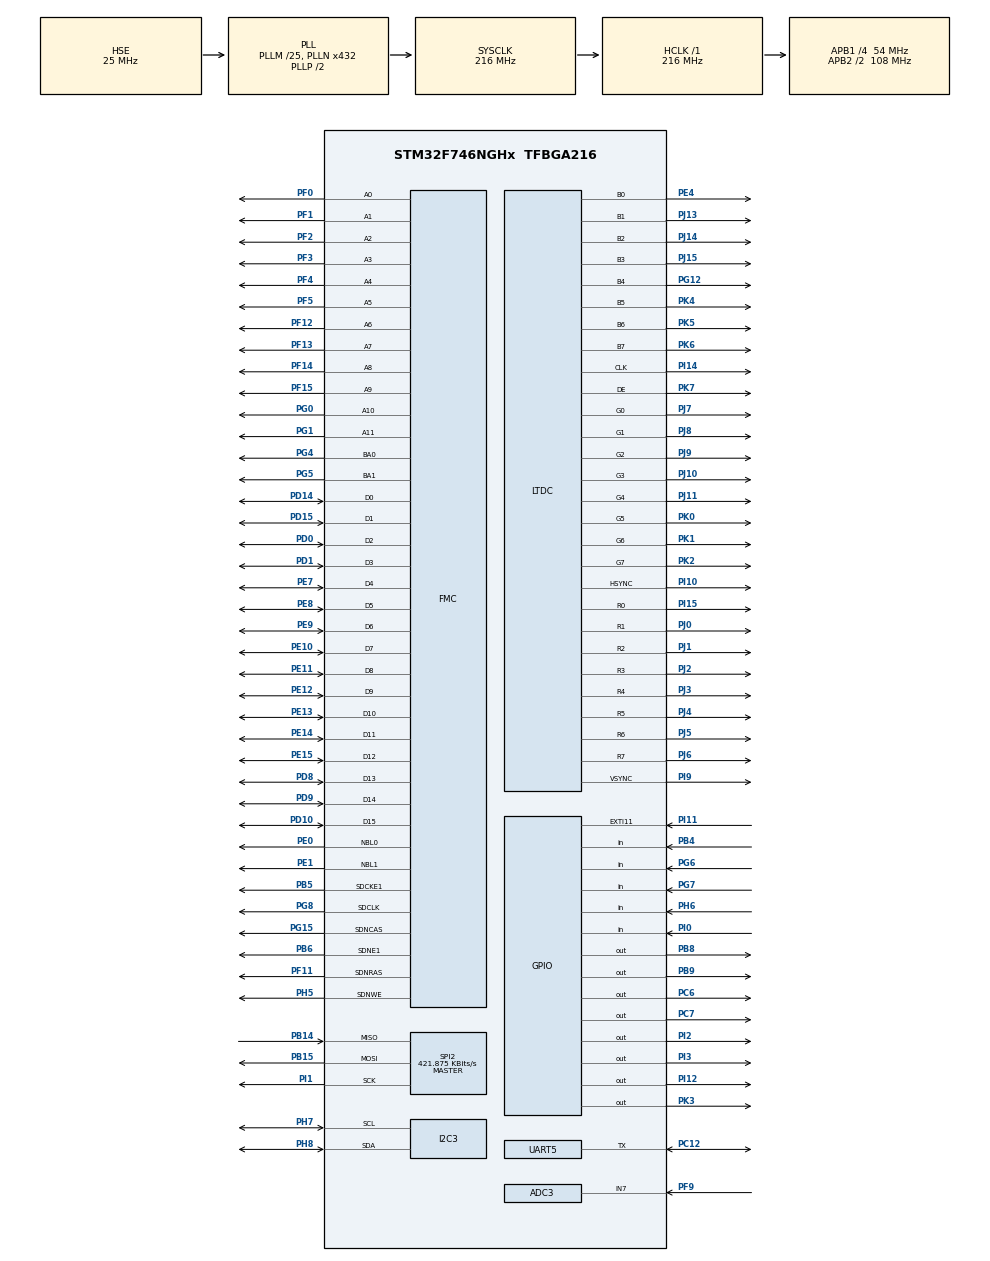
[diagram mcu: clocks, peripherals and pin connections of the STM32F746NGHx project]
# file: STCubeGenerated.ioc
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ADC3.Channel-0\#ChannelRegularConversion=ADC_CHANNEL_7
ADC3.ClockPrescaler=ADC_CLOCK_SYNC_PCLK_DIV4
ADC3.ContinuousConvMode=ENABLE
ADC3.DMAContinuousRequests=ENABLE
ADC3.DataAlign=ADC_DATAALIGN_RIGHT
ADC3.DiscontinuousConvMode=DISABLE
ADC3.EOCSelection=ADC_EOC_SINGLE_CONV
ADC3.EnableAnalogWatchDog=false
ADC3.ExternalTrigConv=ADC_SOFTWARE_START
ADC3.ExternalTrigConvEdge=ADC_EXTERNALTRIGCONVEDGE_NONE
ADC3.InjNumberOfConversion=0
ADC3.NbrOfConversion=1
ADC3.NbrOfConversionFlag=1
ADC3.Rank-0\#ChannelRegularConversion=1
ADC3.Resolution=ADC_RESOLUTION_8B
ADC3.SamplingTime-0\#ChannelRegularConversion=ADC_SAMPLETIME_3CYCLES
ADC3.ScanConvMode=ENABLE
CORTEX_M7.ART_ACCLERATOR_ENABLE=1
CORTEX_M7.AccessPermission-Cortex_Memory_Protection_Unit_Region0_Settings=MPU_REGION_FULL_ACCESS
CORTEX_M7.BaseAddress-Cortex_Memory_Protection_Unit_Region0_Settings=0x20010000
CORTEX_M7.CPU_DCache=Enabled
CORTEX_M7.CPU_ICache=Enabled
CORTEX_M7.Enable-Cortex_Memory_Protection_Unit_Region0_Settings=MPU_REGION_ENABLE
CORTEX_M7.IsCacheable-Cortex_Memory_Protection_Unit_Region0_Settings=MPU_ACCESS_CACHEABLE
CORTEX_M7.MPU_Control=__NULL
CORTEX_M7.PREFETCH_ENABLE=1
CORTEX_M7.Size-Cortex_Memory_Protection_Unit_Region0_Settings=MPU_REGION_SIZE_256KB
DMA2D.ColorMode=DMA2D_OUTPUT_ARGB8888
Dma.ADC3.0.Direction=DMA_PERIPH_TO_MEMORY
Dma.ADC3.0.FIFOMode=DMA_FIFOMODE_DISABLE
Dma.ADC3.0.Instance=DMA2_Stream1
Dma.ADC3.0.MemDataAlignment=DMA_MDATAALIGN_WORD
Dma.ADC3.0.MemInc=DMA_MINC_ENABLE
Dma.ADC3.0.Mode=DMA_NORMAL
Dma.ADC3.0.PeriphDataAlignment=DMA_PDATAALIGN_WORD
Dma.ADC3.0.PeriphInc=DMA_PINC_DISABLE
Dma.ADC3.0.Priority=DMA_PRIORITY_VERY_HIGH
Dma.Request0=ADC3
I2C3.Timing=0x20404768
LTDC.ActiveH=272
LTDC.ActiveW=480
LTDC.Alpha_L0=255
LTDC.HBP=13
LTDC.HFP=32
LTDC.HSync=41
LTDC.ImageHeight_L0=272
LTDC.ImageWidth_L0=480
LTDC.Layers=0
LTDC.VSync=10
LTDC.WindowX1_L0=480
LTDC.WindowY1_L0=272
Mcu.Family=STM32F7
Mcu.Name=STM32F746NGHx
Mcu.Package=TFBGA216
NVIC.DMA2_Stream1_IRQn=true\:1\:0\:true\:false\:true\:true
NVIC.EXTI15_10_IRQn=true\:0\:0\:false\:false\:true\:true
NVIC.PriorityGroup=NVIC_PRIORITYGROUP_4
PA13.Mode=Trace_Asynchronous_SW
PA13.Signal=SYS_JTMS-SWDIO
PA14.Mode=Trace_Asynchronous_SW
PA14.Signal=SYS_JTCK-SWCLK
PB14.Mode=Full_Duplex_Master
PB14.Signal=SPI2_MISO
PB15.Mode=Full_Duplex_Master
PB15.Signal=SPI2_MOSI
PB3.Mode=Trace_Asynchronous_SW
PB3.Signal=SYS_JTDO-SWO
PB4.Signal=GPIO_Input
PB5.Mode=SdramChipSelect2_1
PB5.Signal=FMC_SDCKE1
PB6.Mode=SdramChipSelect2_1
PB6.Signal=FMC_SDNE1
PB8.Signal=GPIO_Output
PB9.Signal=GPIO_Output
PC12.Mode=Half_duplex(single_wire_mode)
PC12.Signal=UART5_TX
PC14/OSC32_IN.Mode=LSE-External-Oscillator
PC14/OSC32_IN.Signal=RCC_OSC32_IN
PC15/OSC32_OUT.Mode=LSE-External-Oscillator
PC15/OSC32_OUT.Signal=RCC_OSC32_OUT
PC6.Signal=GPIO_Output
PC7.Signal=GPIO_Output
PD0.Signal=FMC_D2_DA2
PD1.Signal=FMC_D3_DA3
PD10.Signal=FMC_D15_DA15
PD14.Signal=FMC_D0_DA0
PD15.Signal=FMC_D1_DA1
PD8.Signal=FMC_D13_DA13
PD9.Signal=FMC_D14_DA14
PE0.Signal=FMC_NBL0
PE1.Signal=FMC_NBL1
PE10.Signal=FMC_D7_DA7
PE11.Signal=FMC_D8_DA8
PE12.Signal=FMC_D9_DA9
PE13.Signal=FMC_D10_DA10
PE14.Signal=FMC_D11_DA11
PE15.Signal=FMC_D12_DA12
PE4.Mode=RGB888
PE4.Signal=LTDC_B0
PE7.Signal=FMC_D4_DA4
PE8.Signal=FMC_D5_DA5
PE9.Signal=FMC_D6_DA6
PF0.Signal=FMC_A0
PF1.Signal=FMC_A1
PF11.Signal=FMC_SDNRAS
PF12.Signal=FMC_A6
PF13.Signal=FMC_A7
PF14.Signal=FMC_A8
PF15.Signal=FMC_A9
PF2.Signal=FMC_A2
PF3.Signal=FMC_A3
PF4.Signal=FMC_A4
PF5.Signal=FMC_A5
PF9.Mode=IN7
PF9.Signal=ADC3_IN7
PG0.Signal=FMC_A10
PG1.Signal=FMC_A11
PG12.Mode=RGB888
PG12.Signal=LTDC_B4
PG15.Signal=FMC_SDNCAS
PG4.Signal=FMC_A14_BA0
PG5.Signal=FMC_A15_BA1
PG6.Signal=GPIO_Input
PG7.Signal=GPIO_Input
PG8.Signal=FMC_SDCLK
PH0/OSC_IN.Mode=HSE-External-Oscillator
PH0/OSC_IN.Signal=RCC_OSC_IN
PH1/OSC_OUT.Mode=HSE-External-Oscillator
PH1/OSC_OUT.Signal=RCC_OSC_OUT
PH5.Signal=FMC_SDNWE
PH6.Signal=GPIO_Input
PH7.Mode=I2C
PH7.Signal=I2C3_SCL
PH8.Mode=I2C
PH8.Signal=I2C3_SDA
PI0.Signal=GPIO_Input
PI1.Mode=Full_Duplex_Master
PI1.Signal=SPI2_SCK
PI10.Mode=RGB888
PI10.Signal=LTDC_HSYNC
PI11.Signal=GPXTI11
PI12.GPIO_Speed=GPIO_SPEED_FREQ_HIGH
PI12.PinState=GPIO_PIN_SET
PI12.Signal=GPIO_Output
PI14.Mode=RGB888
PI14.Signal=LTDC_CLK
PI15.Mode=RGB888
PI15.Signal=LTDC_R0
PI2.Signal=GPIO_Output
PI3.Signal=GPIO_Output
PI9.Mode=RGB888
PI9.Signal=LTDC_VSYNC
PJ0.Mode=RGB888
PJ0.Signal=LTDC_R1
PJ1.Mode=RGB888
PJ1.Signal=LTDC_R2
PJ10.Mode=RGB888
PJ10.Signal=LTDC_G3
PJ11.Mode=RGB888
PJ11.Signal=LTDC_G4
PJ13.Mode=RGB888
PJ13.Signal=LTDC_B1
PJ14.Mode=RGB888
PJ14.Signal=LTDC_B2
PJ15.Mode=RGB888
PJ15.Signal=LTDC_B3
PJ2.Mode=RGB888
PJ2.Signal=LTDC_R3
PJ3.Mode=RGB888
PJ3.Signal=LTDC_R4
PJ4.Mode=RGB888
PJ4.Signal=LTDC_R5
PJ5.Mode=RGB888
PJ5.Signal=LTDC_R6
PJ6.Mode=RGB888
PJ6.Signal=LTDC_R7
PJ7.Mode=RGB888
PJ7.Signal=LTDC_G0
PJ8.Mode=RGB888
PJ8.Signal=LTDC_G1
PJ9.Mode=RGB888
PJ9.Signal=LTDC_G2
PK0.Mode=RGB888
PK0.Signal=LTDC_G5
PK1.Mode=RGB888
PK1.Signal=LTDC_G6
PK2.Mode=RGB888
PK2.Signal=LTDC_G7
PK3.GPIO_Speed=GPIO_SPEED_FREQ_HIGH
PK3.PinState=GPIO_PIN_SET
PK3.Signal=GPIO_Output
PK4.Mode=RGB888
PK4.Signal=LTDC_B5
PK5.Mode=RGB888
PK5.Signal=LTDC_B6
PK6.Mode=RGB888
PK6.Signal=LTDC_B7
PK7.Mode=RGB888
PK7.Signal=LTDC_DE
ProjectManager.HeapSize=0x200
ProjectManager.StackSize=0x400
ProjectManager.TargetToolchain=MDK-ARM V5
RCC.AHBFreq_Value=216000000
RCC.APB1CLKDivider=RCC_HCLK_DIV4
RCC.APB1Freq_Value=54000000
RCC.APB1TimFreq_Value=108000000
RCC.APB2CLKDivider=RCC_HCLK_DIV2
RCC.APB2Freq_Value=108000000
RCC.APB2TimFreq_Value=216000000
RCC.CortexFreq_Value=27000000
RCC.Cortex_Div=SYSTICK_CLKSOURCE_HCLK_DIV8
RCC.HCLKFreq_Value=216000000
RCC.HSE_VALUE=25000000
RCC.HSI_VALUE=16000000
RCC.PLLI2SP=RCC_PLLP_DIV2
RCC.PLLM=25
RCC.PLLN=432
RCC.PLLQ=9
RCC.PLLSAIN=100
RCC.PLLSAIP=RCC_PLLSAIP_DIV2
RCC.PLLSourceVirtual=RCC_PLLSOURCE_HSE
RCC.RCC_MCODiv1=RCC_MCODIV_1
RCC.RCC_MCODiv2=RCC_MCODIV_1
RCC.RCC_RTC_Clock_Source_FROM_HSE=RCC_RTCCLKSOURCE_HSE_DIV2
RCC.SYSCLKFreq_VALUE=216000000
RCC.SYSCLKSource=RCC_SYSCLKSOURCE_PLLCLK
RCC.USBFreq_Value=48000000
RCC.VCOOutputFreq_Value=432000000
SH.FMC_A0.0=FMC_A0,12b-sda1
SH.FMC_A1.0=FMC_A1,12b-sda1
SH.FMC_A10.0=FMC_A10,12b-sda1
SH.FMC_A11.0=FMC_A11,12b-sda1
SH.FMC_A14_BA0.0=FMC_BA0,FourSdramBanks1
SH.FMC_A15_BA1.0=FMC_BA1,FourSdramBanks1
SH.FMC_A2.0=FMC_A2,12b-sda1
SH.FMC_A3.0=FMC_A3,12b-sda1
SH.FMC_A4.0=FMC_A4,12b-sda1
SH.FMC_A5.0=FMC_A5,12b-sda1
SH.FMC_A6.0=FMC_A6,12b-sda1
SH.FMC_A7.0=FMC_A7,12b-sda1
SH.FMC_A8.0=FMC_A8,12b-sda1
SH.FMC_A9.0=FMC_A9,12b-sda1
SH.FMC_D0_DA0.0=FMC_D0,sd-16b-d1
SH.FMC_D10_DA10.0=FMC_D10,sd-16b-d1
SH.FMC_D11_DA11.0=FMC_D11,sd-16b-d1
SH.FMC_D12_DA12.0=FMC_D12,sd-16b-d1
SH.FMC_D13_DA13.0=FMC_D13,sd-16b-d1
SH.FMC_D14_DA14.0=FMC_D14,sd-16b-d1
SH.FMC_D15_DA15.0=FMC_D15,sd-16b-d1
SH.FMC_D1_DA1.0=FMC_D1,sd-16b-d1
SH.FMC_D2_DA2.0=FMC_D2,sd-16b-d1
SH.FMC_D3_DA3.0=FMC_D3,sd-16b-d1
SH.FMC_D4_DA4.0=FMC_D4,sd-16b-d1
SH.FMC_D5_DA5.0=FMC_D5,sd-16b-d1
SH.FMC_D6_DA6.0=FMC_D6,sd-16b-d1
SH.FMC_D7_DA7.0=FMC_D7,sd-16b-d1
SH.FMC_D8_DA8.0=FMC_D8,sd-16b-d1
SH.FMC_D9_DA9.0=FMC_D9,sd-16b-d1
SH.FMC_NBL0.0=FMC_NBL0,Sd2ByteEnable1
SH.FMC_NBL1.0=FMC_NBL1,Sd2ByteEnable1
SH.FMC_SDCLK.0=FMC_SDCLK,12b-sda1
SH.FMC_SDNCAS.0=FMC_SDNCAS,12b-sda1
SH.FMC_SDNRAS.0=FMC_SDNRAS,12b-sda1
SH.FMC_SDNWE.0=FMC_SDNWE,12b-sda1
SPI2.BaudRatePrescaler=SPI_BAUDRATEPRESCALER_128
SPI2.CalculateBaudRate=421.875 KBits/s
SPI2.DataSize=SPI_DATASIZE_16BIT
SPI2.Direction=SPI_DIRECTION_2LINES
SPI2.Mode=SPI_MODE_MASTER
SPI2.VirtualType=VM_MASTER
VP_DMA2D_VS_DMA2D.Mode=DMA2D_Activate
board=STCubeGenerated

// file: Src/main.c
/**
  ******************************************************************************
  * File Name          : main.c
  * Description        : Main program body
  ******************************************************************************
  ** This notice applies to any and all portions of this file
  * that are not between comment pairs USER CODE BEGIN and
  * USER CODE END. Other portions of this file, whether
  * inserted by the user or by software development tools
  * are owned by their respective copyright owners.
  *
  * COPYRIGHT(c) 2018 STMicroelectronics
  *
  * Redistribution and use in source and binary forms, with or without modification,
  * are permitted provided that the following conditions are met:
  *   1. Redistributions of source code must retain the above copyright notice,
  *      this list of conditions and the following disclaimer.
  *   2. Redistributions in binary form must reproduce the above copyright notice,
  *      this list of conditions and the following disclaimer in the documentation
  *      and/or other materials provided with the distribution.
  *   3. Neither the name of STMicroelectronics nor the names of its contributors
  *      may be used to endorse or promote products derived from this software
  *      without specific prior written permission.
  *
  * THIS SOFTWARE IS PROVIDED BY THE COPYRIGHT HOLDERS AND CONTRIBUTORS "AS IS"
  * AND ANY EXPRESS OR IMPLIED WARRANTIES, INCLUDING, BUT NOT LIMITED TO, THE
  * IMPLIED WARRANTIES OF MERCHANTABILITY AND FITNESS FOR A PARTICULAR PURPOSE ARE
  * DISCLAIMED. IN NO EVENT SHALL THE COPYRIGHT HOLDER OR CONTRIBUTORS BE LIABLE
  * FOR ANY DIRECT, INDIRECT, INCIDENTAL, SPECIAL, EXEMPLARY, OR CONSEQUENTIAL
  * DAMAGES (INCLUDING, BUT NOT LIMITED TO, PROCUREMENT OF SUBSTITUTE GOODS OR
  * SERVICES; LOSS OF USE, DATA, OR PROFITS; OR BUSINESS INTERRUPTION) HOWEVER
  * CAUSED AND ON ANY THEORY OF LIABILITY, WHETHER IN CONTRACT, STRICT LIABILITY,
  * OR TORT (INCLUDING NEGLIGENCE OR OTHERWISE) ARISING IN ANY WAY OUT OF THE USE
  * OF THIS SOFTWARE, EVEN IF ADVISED OF THE POSSIBILITY OF SUCH DAMAGE.
  *
  ******************************************************************************
  */

#include "main.h"
#include "stm32f7xx_hal.h"

/* USER CODE BEGIN Includes */
#include "stm32746g_discovery_lcd.h"
#include "stm32746g_discovery_ts.h"
#include "splash.h"
#include "gui.h"
#include "ft5336.h"
#include "RGB565_320x240.h"
#include "spi.h"
#include "stm32f7xx_it.h"
#define ITM_Port8(n) (*((volatile unsigned char *)(0xE0000000+4*n)))
/* USER CODE END Includes */

ADC_HandleTypeDef hadc3;
DMA_HandleTypeDef hdma_adc3;

DMA2D_HandleTypeDef hdma2d;

I2C_HandleTypeDef hi2c3;

LTDC_HandleTypeDef hltdc;

SPI_HandleTypeDef hspi2;

UART_HandleTypeDef huart5;

SDRAM_HandleTypeDef hsdram1;

/* USER CODE BEGIN PV */
/* Private variables ---------------------------------------------------------*/
extern uint32_t DMA_compl;

uint32_t no_sample_points = 32768;

uint32_t ADC3ConvertedValues[80000]; //array to store ADC values from DMA

uint32_t TSConvertedValues[2048]; //array to store TS values from DMA

uint32_t run_state = 0; //variable used to store start/stop state 0=stopped, 1=running

uint32_t pga_gain[6] = {0,1,2,3,4,5}; //Gain=1,2,4,5,8,10,16,32

float time_div[8] = {0.25,0.5,1,2.5,5,10,25,50}; //stores t/div shift

uint32_t time_div_selected = 2; //stores which t/div mode is currently selected

int32_t v_shift = 0; //stores vertical offset, (20+)221 = centre of trace area

int32_t h_shift = 0; //stores horizontal offset

uint16_t x, y; //variables to store x,y co-ordinates when user presses touchscreen

uint32_t i_min = 20; //stores the start point of data to plot

uint32_t i_max = 462; //stores the end point of data to plot

int32_t trig_level = 100; //stores the trigger level

uint32_t trigset=0;	//stores the trigger state, 1=set, 0=not set

uint16_t pga_gain_selected = 0;	//stores the current point in the gain array selected

uint32_t attenuation = 1; //1= 1:1, 10= 1:10

uint32_t coup_mode = 0; //stores current coupling mode, 0 = dc, 1 = ac

/* USER CODE END PV */

void SystemClock_Config(void);
static void MX_GPIO_Init(void);
static void MX_DMA_Init(void);
static void MX_ADC3_Init(void);
static void MX_DMA2D_Init(void);
static void MX_FMC_Init(void);
static void MX_LTDC_Init(void);
static void MX_UART5_Init(void);
static void MX_I2C3_Init(void);
static void MX_SPI2_Init(void);

/* USER CODE BEGIN PFP */
void startadc3 (void);
void stopadc3 (void);
/* Private function prototypes -----------------------------------------------*/

/* USER CODE END PFP */

int main(void)
{

  /* Enable I-Cache-------------------------------------------------------------*/
  SCB_EnableICache();

  /* Enable D-Cache-------------------------------------------------------------*/
  SCB_EnableDCache();

  /* MCU Configuration----------------------------------------------------------*/

  /* Reset of all peripherals, Initializes the Flash interface and the Systick. */
  HAL_Init();

  /* Configure the system clock */
  SystemClock_Config();

  /* Initialize all configured peripherals */
  MX_GPIO_Init();
  MX_DMA_Init();
  MX_ADC3_Init();
  MX_DMA2D_Init();
  MX_FMC_Init();
  MX_LTDC_Init();
  MX_UART5_Init();
  MX_I2C3_Init();
  MX_SPI2_Init();

  /* USER CODE BEGIN 2 */

	/*
	// output to the Debug viewer using the ITM
	ITM_Port8(0) = 'a';
	while (ITM_Port8(0) == 0);
	ITM_Port8(0) = 0x0D;
	while (ITM_Port8(0) == 0);
	ITM_Port8(0) = 0x0A;
	*/
  /* LCD Initialization */
	BSP_LCD_Init();
	BSP_LCD_LayerDefaultInit(0, LCD_FB_START_ADDRESS);

  /* Enable the LCD */
  BSP_LCD_DisplayOn();

 /* Configure Front layer (0) */
  BSP_LCD_SelectLayer(0);
  /* Clear the Background Layer */
  BSP_LCD_Clear(LCD_COLOR_BLACK);
  //BSP_LCD_SetTransparency(1,0xFF);
	BSP_LCD_SetTextColor(LCD_COLOR_WHITE);
	BSP_LCD_SetBackColor(LCD_COLOR_BLACK);

	//Initialise Touch Screen
	BSP_TS_Init(480,272);
	printf("LCD initialisation complete\n");

  printf("Waiting for user to dismiss splash screen\n");
	printf("Ensure that AFE is connected\n");

	//Display splash screen on LCD
	drawsplash();

	/* SPI Peripheral Initialisation */
	/* Set the CS high (disable) for DAC & PGA*/
	HAL_GPIO_WritePin(GPIOI, GPIO_PIN_2, GPIO_PIN_SET);
	HAL_GPIO_WritePin(GPIOI, GPIO_PIN_3, GPIO_PIN_SET);

	//Initialise the DAC and PGA
	dac_set_level(0); //zero offset (Vref = 0 V)
	pga_control(0); //zero gain

	/* Initialise the AFE auto-switching as disabled */
	HAL_GPIO_WritePin(GPIOC, GPIO_PIN_6, GPIO_PIN_SET);
	HAL_GPIO_WritePin(GPIOC, GPIO_PIN_7, GPIO_PIN_SET);

	printf("DAC & PGA initialised\n");

  /* Configure Background Layer (1) */
	/* Comment out the following line to disable the background
	   - reduces programming time during testing */
  BSP_LCD_LayerRgb565Init(1, (uint32_t)&RGB565_320x240);
	BSP_LCD_SetTransparency(1, 80);

	//Initialise touch screen in interrupt mode
	BSP_TS_ITConfig();

	cleartrace(); //clear the trace area
	run_state = 1; //Initially start the DSO with trace running
	startadc3(); //start ADC3
	printf("Init completed; DSO started\n");

  /* USER CODE END 2 */

  /* Infinite loop */
  while (1)
  {

  /* USER CODE BEGIN 3 */

		//update the status on LCD
		drawmain();
		drawstatus();

		//if current state = 1, start the DSO
		if (run_state == 1)
		{
			drawrun(); //display DSO running
			startadc3(); //start ADC3
		}
		//otherwise pause the DSO
		else
		{
			drawstop(); //display DSO stopped
			stopadc3();	//stop ADC3
		}
		HAL_Delay(50); //Delay before reloading the ADC + refreshing status
  }

  /* USER CODE END 3 */

}

/** System Clock Configuration
*/
void SystemClock_Config(void)
{

  RCC_OscInitTypeDef RCC_OscInitStruct;
  RCC_ClkInitTypeDef RCC_ClkInitStruct;
  RCC_PeriphCLKInitTypeDef PeriphClkInitStruct;

    /**Configure the main internal regulator output voltage
    */
  __HAL_RCC_PWR_CLK_ENABLE();

  __HAL_PWR_VOLTAGESCALING_CONFIG(PWR_REGULATOR_VOLTAGE_SCALE1);

    /**Initializes the CPU, AHB and APB busses clocks
    */
  RCC_OscInitStruct.OscillatorType = RCC_OSCILLATORTYPE_HSE;
  RCC_OscInitStruct.HSEState = RCC_HSE_ON;
  RCC_OscInitStruct.PLL.PLLState = RCC_PLL_ON;
  RCC_OscInitStruct.PLL.PLLSource = RCC_PLLSOURCE_HSE;
  RCC_OscInitStruct.PLL.PLLM = 25;
  RCC_OscInitStruct.PLL.PLLN = 432;
  RCC_OscInitStruct.PLL.PLLP = RCC_PLLP_DIV2;
  RCC_OscInitStruct.PLL.PLLQ = 9;
  if (HAL_RCC_OscConfig(&RCC_OscInitStruct) != HAL_OK)
  {
    _Error_Handler(__FILE__, __LINE__);
  }

    /**Activate the Over-Drive mode
    */
  if (HAL_PWREx_EnableOverDrive() != HAL_OK)
  {
    _Error_Handler(__FILE__, __LINE__);
  }

    /**Initializes the CPU, AHB and APB busses clocks
    */
  RCC_ClkInitStruct.ClockType = RCC_CLOCKTYPE_HCLK|RCC_CLOCKTYPE_SYSCLK
                              |RCC_CLOCKTYPE_PCLK1|RCC_CLOCKTYPE_PCLK2;
  RCC_ClkInitStruct.SYSCLKSource = RCC_SYSCLKSOURCE_PLLCLK;
  RCC_ClkInitStruct.AHBCLKDivider = RCC_SYSCLK_DIV1;
  RCC_ClkInitStruct.APB1CLKDivider = RCC_HCLK_DIV4;
  RCC_ClkInitStruct.APB2CLKDivider = RCC_HCLK_DIV2;

  if (HAL_RCC_ClockConfig(&RCC_ClkInitStruct, FLASH_LATENCY_7) != HAL_OK)
  {
    _Error_Handler(__FILE__, __LINE__);
  }

  PeriphClkInitStruct.PeriphClockSelection = RCC_PERIPHCLK_LTDC|RCC_PERIPHCLK_UART5
                              |RCC_PERIPHCLK_I2C3;
  PeriphClkInitStruct.PLLSAI.PLLSAIN = 100;
  PeriphClkInitStruct.PLLSAI.PLLSAIR = 2;
  PeriphClkInitStruct.PLLSAI.PLLSAIQ = 2;
  PeriphClkInitStruct.PLLSAI.PLLSAIP = RCC_PLLSAIP_DIV2;
  PeriphClkInitStruct.PLLSAIDivQ = 1;
  PeriphClkInitStruct.PLLSAIDivR = RCC_PLLSAIDIVR_2;
  PeriphClkInitStruct.Uart5ClockSelection = RCC_UART5CLKSOURCE_PCLK1;
  PeriphClkInitStruct.I2c3ClockSelection = RCC_I2C3CLKSOURCE_PCLK1;
  if (HAL_RCCEx_PeriphCLKConfig(&PeriphClkInitStruct) != HAL_OK)
  {
    _Error_Handler(__FILE__, __LINE__);
  }

    /**Configure the Systick interrupt time
    */
  HAL_SYSTICK_Config(HAL_RCC_GetHCLKFreq()/8000);

    /**Configure the Systick
    */
  HAL_SYSTICK_CLKSourceConfig(SYSTICK_CLKSOURCE_HCLK_DIV8);

  /* SysTick_IRQn interrupt configuration */
  HAL_NVIC_SetPriority(SysTick_IRQn, 0, 0);
}

/* ADC3 init function */
static void MX_ADC3_Init(void)
{

  ADC_ChannelConfTypeDef sConfig;

    /**Configure the global features of the ADC (Clock, Resolution, Data Alignment and number of conversion)
    */
  hadc3.Instance = ADC3;
  hadc3.Init.ClockPrescaler = ADC_CLOCK_SYNC_PCLK_DIV4;
  hadc3.Init.Resolution = ADC_RESOLUTION_8B;
  hadc3.Init.ScanConvMode = ENABLE;
  hadc3.Init.ContinuousConvMode = ENABLE;
  hadc3.Init.DiscontinuousConvMode = DISABLE;
  hadc3.Init.ExternalTrigConvEdge = ADC_EXTERNALTRIGCONVEDGE_NONE;
  hadc3.Init.ExternalTrigConv = ADC_SOFTWARE_START;
  hadc3.Init.DataAlign = ADC_DATAALIGN_RIGHT;
  hadc3.Init.NbrOfConversion = 1;
  hadc3.Init.DMAContinuousRequests = ENABLE;
  hadc3.Init.EOCSelection = ADC_EOC_SINGLE_CONV;
  if (HAL_ADC_Init(&hadc3) != HAL_OK)
  {
    _Error_Handler(__FILE__, __LINE__);
  }

    /**Configure for the selected ADC regular channel its corresponding rank in the sequencer and its sample time.
    */
  sConfig.Channel = ADC_CHANNEL_7;
  sConfig.Rank = 1;
  sConfig.SamplingTime = ADC_SAMPLETIME_3CYCLES;
  if (HAL_ADC_ConfigChannel(&hadc3, &sConfig) != HAL_OK)
  {
    _Error_Handler(__FILE__, __LINE__);
  }

}

/* DMA2D init function */
static void MX_DMA2D_Init(void)
{

  hdma2d.Instance = DMA2D;
  hdma2d.Init.Mode = DMA2D_M2M;
  hdma2d.Init.ColorMode = DMA2D_OUTPUT_ARGB8888;
  hdma2d.Init.OutputOffset = 0;
  hdma2d.LayerCfg[1].InputOffset = 0;
  hdma2d.LayerCfg[1].InputColorMode = DMA2D_INPUT_ARGB8888;
  hdma2d.LayerCfg[1].AlphaMode = DMA2D_NO_MODIF_ALPHA;
  hdma2d.LayerCfg[1].InputAlpha = 0;
  if (HAL_DMA2D_Init(&hdma2d) != HAL_OK)
  {
    _Error_Handler(__FILE__, __LINE__);
  }

  if (HAL_DMA2D_ConfigLayer(&hdma2d, 1) != HAL_OK)
  {
    _Error_Handler(__FILE__, __LINE__);
  }

}

/* I2C3 init function */
static void MX_I2C3_Init(void)
{

  hi2c3.Instance = I2C3;
  hi2c3.Init.Timing = 0x20404768;
  hi2c3.Init.OwnAddress1 = 0;
  hi2c3.Init.AddressingMode = I2C_ADDRESSINGMODE_7BIT;
  hi2c3.Init.DualAddressMode = I2C_DUALADDRESS_DISABLE;
  hi2c3.Init.OwnAddress2 = 0;
  hi2c3.Init.OwnAddress2Masks = I2C_OA2_NOMASK;
  hi2c3.Init.GeneralCallMode = I2C_GENERALCALL_DISABLE;
  hi2c3.Init.NoStretchMode = I2C_NOSTRETCH_DISABLE;
  if (HAL_I2C_Init(&hi2c3) != HAL_OK)
  {
    _Error_Handler(__FILE__, __LINE__);
  }

    /**Configure Analogue filter
    */
  if (HAL_I2CEx_ConfigAnalogFilter(&hi2c3, I2C_ANALOGFILTER_ENABLE) != HAL_OK)
  {
    _Error_Handler(__FILE__, __LINE__);
  }

    /**Configure Digital filter
    */
  if (HAL_I2CEx_ConfigDigitalFilter(&hi2c3, 0) != HAL_OK)
  {
    _Error_Handler(__FILE__, __LINE__);
  }

}

/* LTDC init function */
static void MX_LTDC_Init(void)
{

  LTDC_LayerCfgTypeDef pLayerCfg;

  hltdc.Instance = LTDC;
  hltdc.Init.HSPolarity = LTDC_HSPOLARITY_AL;
  hltdc.Init.VSPolarity = LTDC_VSPOLARITY_AL;
  hltdc.Init.DEPolarity = LTDC_DEPOLARITY_AL;
  hltdc.Init.PCPolarity = LTDC_PCPOLARITY_IPC;
  hltdc.Init.HorizontalSync = 40;
  hltdc.Init.VerticalSync = 9;
  hltdc.Init.AccumulatedHBP = 53;
  hltdc.Init.AccumulatedVBP = 11;
  hltdc.Init.AccumulatedActiveW = 533;
  hltdc.Init.AccumulatedActiveH = 283;
  hltdc.Init.TotalWidth = 565;
  hltdc.Init.TotalHeigh = 285;
  hltdc.Init.Backcolor.Blue = 0;
  hltdc.Init.Backcolor.Green = 0;
  hltdc.Init.Backcolor.Red = 0;
  if (HAL_LTDC_Init(&hltdc) != HAL_OK)
  {
    _Error_Handler(__FILE__, __LINE__);
  }

  pLayerCfg.WindowX0 = 0;
  pLayerCfg.WindowX1 = 480;
  pLayerCfg.WindowY0 = 0;
  pLayerCfg.WindowY1 = 272;
  pLayerCfg.PixelFormat = LTDC_PIXEL_FORMAT_ARGB8888;
  pLayerCfg.Alpha = 255;
  pLayerCfg.Alpha0 = 0;
  pLayerCfg.BlendingFactor1 = LTDC_BLENDING_FACTOR1_CA;
  pLayerCfg.BlendingFactor2 = LTDC_BLENDING_FACTOR2_CA;
  pLayerCfg.FBStartAdress = 0;
  pLayerCfg.ImageWidth = 480;
  pLayerCfg.ImageHeight = 272;
  pLayerCfg.Backcolor.Blue = 0;
  pLayerCfg.Backcolor.Green = 0;
  pLayerCfg.Backcolor.Red = 0;
  if (HAL_LTDC_ConfigLayer(&hltdc, &pLayerCfg, 0) != HAL_OK)
  {
    _Error_Handler(__FILE__, __LINE__);
  }

}

/* SPI2 init function */
static void MX_SPI2_Init(void)
{

  /* SPI2 parameter configuration*/
  hspi2.Instance = SPI2;
  hspi2.Init.Mode = SPI_MODE_MASTER;
  hspi2.Init.Direction = SPI_DIRECTION_2LINES;
  hspi2.Init.DataSize = SPI_DATASIZE_16BIT;
  hspi2.Init.CLKPolarity = SPI_POLARITY_LOW;
  hspi2.Init.CLKPhase = SPI_PHASE_1EDGE;
  hspi2.Init.NSS = SPI_NSS_SOFT;
  hspi2.Init.BaudRatePrescaler = SPI_BAUDRATEPRESCALER_128;
  hspi2.Init.FirstBit = SPI_FIRSTBIT_MSB;
  hspi2.Init.TIMode = SPI_TIMODE_DISABLE;
  hspi2.Init.CRCCalculation = SPI_CRCCALCULATION_DISABLE;
  hspi2.Init.CRCPolynomial = 7;
  hspi2.Init.CRCLength = SPI_CRC_LENGTH_DATASIZE;
  hspi2.Init.NSSPMode = SPI_NSS_PULSE_ENABLE;
  if (HAL_SPI_Init(&hspi2) != HAL_OK)
  {
    _Error_Handler(__FILE__, __LINE__);
  }

}

/* UART5 init function */
static void MX_UART5_Init(void)
{

  huart5.Instance = UART5;
  huart5.Init.BaudRate = 115200;
  huart5.Init.WordLength = UART_WORDLENGTH_7B;
  huart5.Init.StopBits = UART_STOPBITS_1;
  huart5.Init.Parity = UART_PARITY_NONE;
  huart5.Init.Mode = UART_MODE_TX_RX;
  huart5.Init.HwFlowCtl = UART_HWCONTROL_NONE;
  huart5.Init.OverSampling = UART_OVERSAMPLING_16;
  huart5.Init.OneBitSampling = UART_ONE_BIT_SAMPLE_DISABLE;
  huart5.AdvancedInit.AdvFeatureInit = UART_ADVFEATURE_NO_INIT;
  if (HAL_HalfDuplex_Init(&huart5) != HAL_OK)
  {
    _Error_Handler(__FILE__, __LINE__);
  }

}

static void MX_DMA_Init(void)
{
  /* DMA controller clock enable */
  __HAL_RCC_DMA2_CLK_ENABLE();

  /* DMA interrupt init */
  /* DMA2_Stream1_IRQn interrupt configuration */
  HAL_NVIC_SetPriority(DMA2_Stream1_IRQn, 1, 0);
  HAL_NVIC_EnableIRQ(DMA2_Stream1_IRQn);

}
/* FMC initialization function */
static void MX_FMC_Init(void)
{
  FMC_SDRAM_TimingTypeDef SdramTiming;

  /** Perform the SDRAM1 memory initialization sequence
  */
  hsdram1.Instance = FMC_SDRAM_DEVICE;
  /* hsdram1.Init */
  hsdram1.Init.SDBank = FMC_SDRAM_BANK2;
  hsdram1.Init.ColumnBitsNumber = FMC_SDRAM_COLUMN_BITS_NUM_8;
  hsdram1.Init.RowBitsNumber = FMC_SDRAM_ROW_BITS_NUM_12;
  hsdram1.Init.MemoryDataWidth = FMC_SDRAM_MEM_BUS_WIDTH_16;
  hsdram1.Init.InternalBankNumber = FMC_SDRAM_INTERN_BANKS_NUM_4;
  hsdram1.Init.CASLatency = FMC_SDRAM_CAS_LATENCY_1;
  hsdram1.Init.WriteProtection = FMC_SDRAM_WRITE_PROTECTION_DISABLE;
  hsdram1.Init.SDClockPeriod = FMC_SDRAM_CLOCK_DISABLE;
  hsdram1.Init.ReadBurst = FMC_SDRAM_RBURST_DISABLE;
  hsdram1.Init.ReadPipeDelay = FMC_SDRAM_RPIPE_DELAY_0;
  /* SdramTiming */
  SdramTiming.LoadToActiveDelay = 16;
  SdramTiming.ExitSelfRefreshDelay = 16;
  SdramTiming.SelfRefreshTime = 16;
  SdramTiming.RowCycleDelay = 16;
  SdramTiming.WriteRecoveryTime = 16;
  SdramTiming.RPDelay = 16;
  SdramTiming.RCDDelay = 16;

  if (HAL_SDRAM_Init(&hsdram1, &SdramTiming) != HAL_OK)
  {
    _Error_Handler(__FILE__, __LINE__);
  }

}

/** Configure pins as
        * Analog
        * Input
        * Output
        * EVENT_OUT
        * EXTI
*/
static void MX_GPIO_Init(void)
{

  GPIO_InitTypeDef GPIO_InitStruct;

  /* GPIO Ports Clock Enable */
  __HAL_RCC_GPIOE_CLK_ENABLE();
  __HAL_RCC_GPIOB_CLK_ENABLE();
  __HAL_RCC_GPIOC_CLK_ENABLE();
  __HAL_RCC_GPIOA_CLK_ENABLE();
  __HAL_RCC_GPIOG_CLK_ENABLE();
  __HAL_RCC_GPIOJ_CLK_ENABLE();
  __HAL_RCC_GPIOD_CLK_ENABLE();
  __HAL_RCC_GPIOK_CLK_ENABLE();
  __HAL_RCC_GPIOI_CLK_ENABLE();
  __HAL_RCC_GPIOF_CLK_ENABLE();
  __HAL_RCC_GPIOH_CLK_ENABLE();

  /*Configure GPIO pin Output Level */
  HAL_GPIO_WritePin(GPIOB, GPIO_PIN_8|GPIO_PIN_9, GPIO_PIN_RESET);

  /*Configure GPIO pin Output Level */
  HAL_GPIO_WritePin(GPIOI, GPIO_PIN_3|GPIO_PIN_2, GPIO_PIN_RESET);

  /*Configure GPIO pin Output Level */
  HAL_GPIO_WritePin(GPIOK, GPIO_PIN_3, GPIO_PIN_SET);

  /*Configure GPIO pin Output Level */
  HAL_GPIO_WritePin(GPIOI, GPIO_PIN_12, GPIO_PIN_SET);

  /*Configure GPIO pin Output Level */
  HAL_GPIO_WritePin(GPIOC, GPIO_PIN_7|GPIO_PIN_6, GPIO_PIN_RESET);

  /*Configure GPIO pins : PB8 PB9 */
  GPIO_InitStruct.Pin = GPIO_PIN_8|GPIO_PIN_9;
  GPIO_InitStruct.Mode = GPIO_MODE_OUTPUT_PP;
  GPIO_InitStruct.Pull = GPIO_NOPULL;
  GPIO_InitStruct.Speed = GPIO_SPEED_FREQ_LOW;
  HAL_GPIO_Init(GPIOB, &GPIO_InitStruct);

  /*Configure GPIO pin : PB4 */
  GPIO_InitStruct.Pin = GPIO_PIN_4;
  GPIO_InitStruct.Mode = GPIO_MODE_INPUT;
  GPIO_InitStruct.Pull = GPIO_NOPULL;
  HAL_GPIO_Init(GPIOB, &GPIO_InitStruct);

  /*Configure GPIO pins : PI3 PI2 */
  GPIO_InitStruct.Pin = GPIO_PIN_3|GPIO_PIN_2;
  GPIO_InitStruct.Mode = GPIO_MODE_OUTPUT_PP;
  GPIO_InitStruct.Pull = GPIO_NOPULL;
  GPIO_InitStruct.Speed = GPIO_SPEED_FREQ_LOW;
  HAL_GPIO_Init(GPIOI, &GPIO_InitStruct);

  /*Configure GPIO pin : PK3 */
  GPIO_InitStruct.Pin = GPIO_PIN_3;
  GPIO_InitStruct.Mode = GPIO_MODE_OUTPUT_PP;
  GPIO_InitStruct.Pull = GPIO_NOPULL;
  GPIO_InitStruct.Speed = GPIO_SPEED_FREQ_HIGH;
  HAL_GPIO_Init(GPIOK, &GPIO_InitStruct);

  /*Configure GPIO pin : PI12 */
  GPIO_InitStruct.Pin = GPIO_PIN_12;
  GPIO_InitStruct.Mode = GPIO_MODE_OUTPUT_PP;
  GPIO_InitStruct.Pull = GPIO_NOPULL;
  GPIO_InitStruct.Speed = GPIO_SPEED_FREQ_HIGH;
  HAL_GPIO_Init(GPIOI, &GPIO_InitStruct);

  /*Configure GPIO pin : PI0 */
  GPIO_InitStruct.Pin = GPIO_PIN_0;
  GPIO_InitStruct.Mode = GPIO_MODE_INPUT;
  GPIO_InitStruct.Pull = GPIO_NOPULL;
  HAL_GPIO_Init(GPIOI, &GPIO_InitStruct);

  /*Configure GPIO pin : PI11 */
  GPIO_InitStruct.Pin = GPIO_PIN_11;
  GPIO_InitStruct.Mode = GPIO_MODE_IT_RISING;
  GPIO_InitStruct.Pull = GPIO_NOPULL;
  HAL_GPIO_Init(GPIOI, &GPIO_InitStruct);

  /*Configure GPIO pins : PC7 PC6 */
  GPIO_InitStruct.Pin = GPIO_PIN_7|GPIO_PIN_6;
  GPIO_InitStruct.Mode = GPIO_MODE_OUTPUT_PP;
  GPIO_InitStruct.Pull = GPIO_NOPULL;
  GPIO_InitStruct.Speed = GPIO_SPEED_FREQ_LOW;
  HAL_GPIO_Init(GPIOC, &GPIO_InitStruct);

  /*Configure GPIO pins : PG7 PG6 */
  GPIO_InitStruct.Pin = GPIO_PIN_7|GPIO_PIN_6;
  GPIO_InitStruct.Mode = GPIO_MODE_INPUT;
  GPIO_InitStruct.Pull = GPIO_NOPULL;
  HAL_GPIO_Init(GPIOG, &GPIO_InitStruct);

  /*Configure GPIO pin : PH6 */
  GPIO_InitStruct.Pin = GPIO_PIN_6;
  GPIO_InitStruct.Mode = GPIO_MODE_INPUT;
  GPIO_InitStruct.Pull = GPIO_NOPULL;
  HAL_GPIO_Init(GPIOH, &GPIO_InitStruct);

  /* EXTI interrupt init*/
  HAL_NVIC_SetPriority(EXTI15_10_IRQn, 0, 0);
  HAL_NVIC_EnableIRQ(EXTI15_10_IRQn);

}

/* USER CODE BEGIN 4 */

void startadc3 (void)
{
		//Starts ADC3
		if(HAL_ADC_Start(&hadc3) != HAL_OK)
		{
			//print error if cannot start
			printf("HAL_ADC_Start error!\n");
		}

		//Starts ADC3 DMA request
		if (HAL_ADC_Start_DMA(&hadc3, (uint32_t*)ADC3ConvertedValues, no_sample_points) != HAL_OK)
		{
			//print error if cannot start
			printf("HAL_ADC_Start_DMA error!\n");
		}

}

void stopadc3 (void)
{
		//Stops ADC3 DMA request
		HAL_ADC_Stop_DMA(&hadc3);
}

/* USER CODE END 4 */

void _Error_Handler(char * file, int line)
{
  while(1)
  {
  }
}

/************************ (C) COPYRIGHT STMicroelectronics *****END OF FILE****/
